# STM32WL5x_CM0P register map
File version: 1.5
CPU: CM0 r0p1, little endian, MPU, no FPU, 4 interrupt priority bits
Registers are 32-bit, read-write, reset 0x0 unless marked. A register's access mark holds for its fields unless they carry their own. Offsets are from the block's base; [hi:lo] are bit positions; {n}, {i} and the like mark numbered series.

## SYSCFG — System configuration controller
Base 0x40010000
0x00 MEMRMP — memory remap register
  [2:0] MEM_MODE — Memory mapping selection
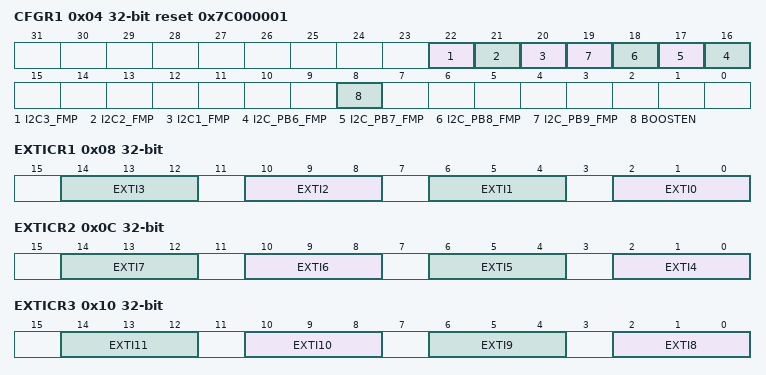
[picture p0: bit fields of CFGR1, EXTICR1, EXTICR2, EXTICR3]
0x04 CFGR1 reset 0x7C000001 — configuration register 1
  [22] I2C3_FMP — I2C3 Fast-mode Plus driving capability activation
  [21] I2C2_FMP — I2C2 Fast-mode Plus driving capability activation
  [20] I2C1_FMP — I2C1 Fast-mode Plus driving capability activation
  [n+10] I2C_PB{n}_FMP (n=6..9) — Fast-mode Plus (Fm+) driving capability activation on PB{n}
  [8] BOOSTEN — I/O analog switch voltage booster enable
0x08 EXTICR1 — external interrupt configuration register 1
  [4n+2:4n] EXTI{n} (n=0..3) — EXTI {n} configuration bits
0x0C EXTICR2 — external interrupt configuration register 2
  [4n-14:4n-16] EXTI{n} (n=4..7) — EXTI {n} configuration bits
0x10 EXTICR3 — external interrupt configuration register 3
  [4n-30:4n-32] EXTI{n} (n=8..11) — EXTI {n} configuration bits
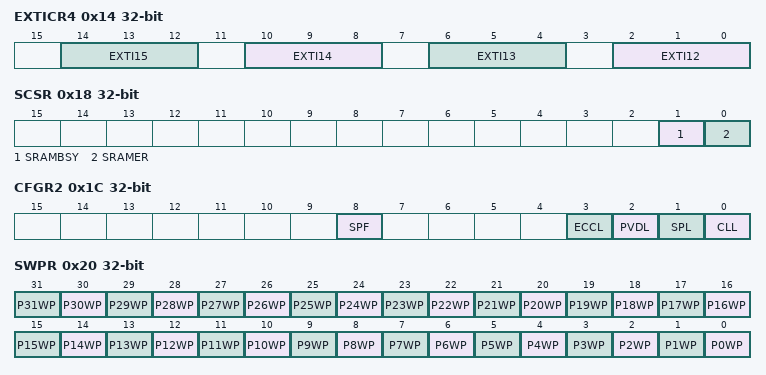
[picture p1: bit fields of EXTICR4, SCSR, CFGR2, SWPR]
0x14 EXTICR4 — external interrupt configuration register 4
  [4n-46:4n-48] EXTI{n} (n=12..15) — EXTI{n} configuration bits
0x18 SCSR access per field
  [1] SRAMBSY ro — SRAM1, SRAM2 and PKA SRAM busy by erase operation
  [0] SRAMER rw — SRAM1, SRAM2 and PKA SRAM Erase
0x1C CFGR2 access per field
  [8] SPF rw — SRAM2 parity error flag
  [3] ECCL wo — ECC Lock
  [2] PVDL wo — PVD lock enable bit
  [1] SPL wo — SRAM2 parity lock bit
  [0] CLL wo — CPU1 LOCKUP (Hardfault) output enable bit
0x20 SWPR wo
  [n] P{n}WP (n=0..31) — SRAM2 1Kbyte page {n} write protection
0x24 SKR wo
  [7:0] KEY — SRAM2 write protection key for software erase

## LPTIM1 — Low-power timer
Base 0x40007C00
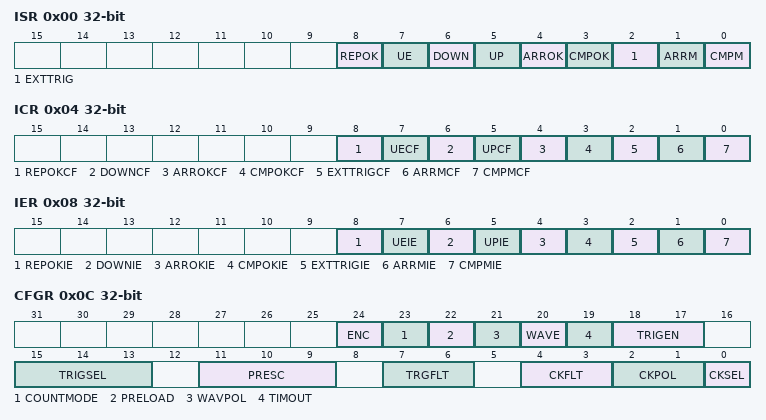
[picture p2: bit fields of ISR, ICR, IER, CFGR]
0x00 ISR ro — interrupt and status register
  [8] REPOK — Repetition register update Ok
  [7] UE — LPTIM update event occurred
  [6] DOWN — Counter direction change up to down
  [5] UP — Counter direction change down to up
  [4] ARROK — Autoreload register update OK
  [3] CMPOK — Compare register update OK
  [2] EXTTRIG — External trigger edge event
  [1] ARRM — Autoreload match
  [0] CMPM — Compare match
0x04 ICR wo — interrupt clear register
  [8] REPOKCF — Repetition register update OK clear flag
  [7] UECF — Update event clear flag
  [6] DOWNCF — Direction change to down Clear Flag
  [5] UPCF — Direction change to UP Clear Flag
  [4] ARROKCF — Autoreload register update OK Clear Flag
  [3] CMPOKCF — Compare register update OK Clear Flag
  [2] EXTTRIGCF — External trigger valid edge Clear Flag
  [1] ARRMCF — Autoreload match Clear Flag
  [0] CMPMCF — compare match Clear Flag
0x08 IER — interrupt enable register
  [8] REPOKIE — Repetition register update OK interrupt Enable
  [7] UEIE — Update event interrupt enable
  [6] DOWNIE — Direction change to down Interrupt Enable
  [5] UPIE — Direction change to UP Interrupt Enable
  [4] ARROKIE — Autoreload register update OK Interrupt Enable
  [3] CMPOKIE — Compare register update OK Interrupt Enable
  [2] EXTTRIGIE — External trigger valid edge Interrupt Enable
  [1] ARRMIE — Autoreload match Interrupt Enable
  [0] CMPMIE — Compare match Interrupt Enable
0x0C CFGR — configuration register
  [24] ENC, [23] COUNTMODE, [22] PRELOAD, [21] WAVPOL, [20] WAVE, [19] TIMOUT, [18:17] TRIGEN, [15:13] TRIGSEL, [11:9] PRESC, [7:6] TRGFLT, [4:3] CKFLT, [2:1] CKPOL, [0] CKSEL
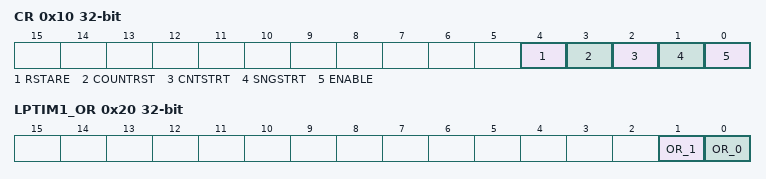
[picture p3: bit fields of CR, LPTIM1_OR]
0x10 CR — control register
  [4] RSTARE, [3] COUNTRST, [2] CNTSTRT, [1] SNGSTRT, [0] ENABLE
0x14 CMP — compare register
  [15:0] CMP
0x18 ARR reset 0x1 — autoreload register
  [15:0] ARR — Auto reload value
0x1C CNT ro — counter register
  [15:0] CNT — Counter value
0x20 LPTIM1_OR — option register
  [1] OR_1 — Option register bit 1
  [0] OR_0 — Option register bit 0
0x28 RCR — repetition register
  [7:0] REP — Repetition register value

## LPTIM2 — Low-power timer
Base 0x40009400
Registers as LPTIM1 (with LPTIM1 read as LPTIM2).

## LPTIM3 — Low-power timer
Base 0x40009800
Registers as LPTIM1 (with LPTIM1 read as LPTIM3).
